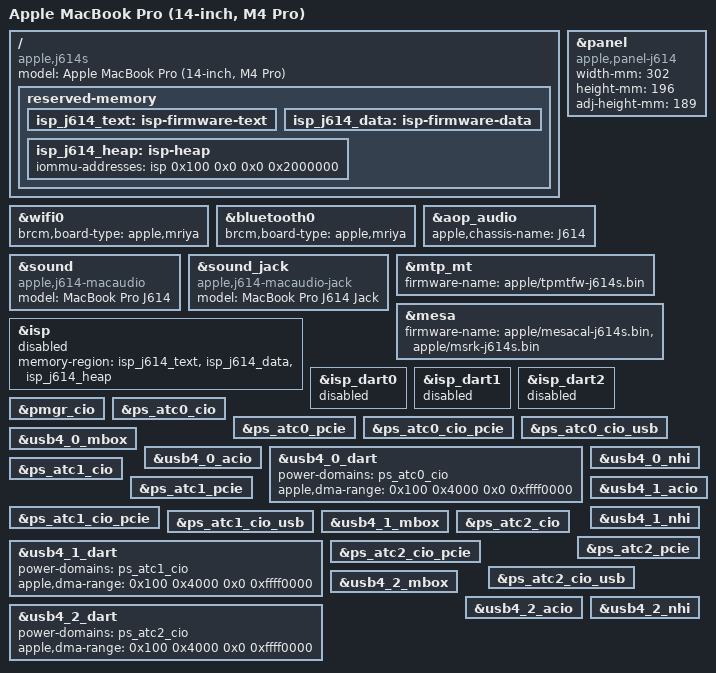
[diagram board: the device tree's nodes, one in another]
// SPDX-License-Identifier: GPL-2.0+ OR MIT
/*
 * MacBook Pro (14-inch, M4 Pro)
 *
 * target-type: J614s
 *
 * Copyright The Asahi Linux Contributors
 */

/dts-v1/;

#include "t6040.dtsi"
#include "t604x-j614-j616.dtsi"

/ {
	compatible = "apple,j614s", "apple,t6040", "apple,arm-platform";
	model = "Apple MacBook Pro (14-inch, M4 Pro)";
};

/* ADT /arm-io/wlan module-instance */
&wifi0 {
	brcm,board-type = "apple,mriya";
};

&bluetooth0 {
	brcm,board-type = "apple,mriya";
};

&panel {
	compatible = "apple,panel-j614", "apple,panel-mini-led", "apple,panel";
	width-mm = <302>;
	height-mm = <196>;
	adj-height-mm = <189>;
};

&aop_audio {
	apple,chassis-name = "J614";
};

/*
 * The speakers, as on the J616s: the same six amps, slots and frame (the
 * boot loader copies each amp's ADT speaker-config row). Playback waits for
 * a protection lease, which speakerguardd v2 takes only after compiling and
 * self-checking this Mac's own tuning; the legacy protection has no J614
 * profile, so without v2 the amps stay at the kernel's floor.
 */
&sound {
	compatible = "apple,j614-macaudio", "apple,macaudio";
	model = "MacBook Pro J614";
};

&sound_jack {
	compatible = "apple,j614-macaudio-jack", "apple,macaudio";
	model = "MacBook Pro J614 Jack";
};

&mtp_mt {
	firmware-name = "apple/tpmtfw-j614s.bin";
};

/*
 * Per-device factory data from this Mac's own iBoot system container: the
 * sealed calibration and the sealed root key.
 */
&mesa {
	firmware-name = "apple/mesacal-j614s.bin", "apple/msrk-j614s.bin";
};

/* The loader reserves this boot's ISP firmware before enabling the camera. */
&isp {
	memory-region = <&isp_j614_text>, <&isp_j614_data>, <&isp_j614_heap>;
	status = "disabled";
};

/delete-node/ &isp_fw_text;
/delete-node/ &isp_fw_data;
/delete-node/ &isp_heap;

/ {
	reserved-memory {
		isp_j614_text: isp-firmware-text { };
		isp_j614_data: isp-firmware-data { };
		isp_j614_heap: isp-heap {
			iommu-addresses = <&isp 0x100 0x0 0x0 0x2000000>;
		};
	};
};

&isp_dart0 {
	status = "disabled";
};

&isp_dart1 {
	status = "disabled";
};

&isp_dart2 {
	status = "disabled";
};

/*
 * USB4/Thunderbolt on all three Type-C ports: typec0 (left back, ACIO0),
 * typec1 (left front, ACIO1) and typec2 (right, ACIO2), as on the J616s: the
 * J614s ADT has the same acio0-2, dart-acio0-2 and acio-cpu0-2. The loader
 * hands each router its router, adapter and NHI tuning and its DROM over. No
 * PCIe tunnels yet: host-to-host (XDomain, thunderbolt-net) and USB4 links
 * only.
 */
&pmgr_cio {
	status = "okay";
};

&ps_atc0_cio {
	status = "okay";
};

&ps_atc0_pcie {
	status = "okay";
};

&ps_atc0_cio_pcie {
	status = "okay";
};

&ps_atc0_cio_usb {
	status = "okay";
};

&usb4_0_mbox {
	status = "okay";
};

&usb4_0_acio {
	/delete-property/ apple,pcie-tunnel;
	status = "okay";
};

&usb4_0_dart {
	power-domains = <&ps_atc0_cio>;
	/* ADT dart-acio0 vm-base: the NHI addresses its rings below 1 TiB + 4 GiB. */
	apple,dma-range = <0x100 0x4000 0x0 0xffff0000>;
	status = "okay";
};

&usb4_0_nhi {
	status = "okay";
};

&ps_atc1_cio {
	status = "okay";
};

&ps_atc1_pcie {
	status = "okay";
};

&ps_atc1_cio_pcie {
	status = "okay";
};

&ps_atc1_cio_usb {
	status = "okay";
};

&usb4_1_mbox {
	status = "okay";
};

&usb4_1_acio {
	/delete-property/ apple,pcie-tunnel;
	status = "okay";
};

&usb4_1_dart {
	power-domains = <&ps_atc1_cio>;
	/* The same DVA window as the ACIO0 router DART. */
	apple,dma-range = <0x100 0x4000 0x0 0xffff0000>;
	status = "okay";
};

&usb4_1_nhi {
	status = "okay";
};

&ps_atc2_cio {
	status = "okay";
};

&ps_atc2_pcie {
	status = "okay";
};

&ps_atc2_cio_pcie {
	status = "okay";
};

&ps_atc2_cio_usb {
	status = "okay";
};

&usb4_2_mbox {
	status = "okay";
};

&usb4_2_acio {
	/delete-property/ apple,pcie-tunnel;
	status = "okay";
};

&usb4_2_dart {
	power-domains = <&ps_atc2_cio>;
	/* The same DVA window as the ACIO0 router DART. */
	apple,dma-range = <0x100 0x4000 0x0 0xffff0000>;
	status = "okay";
};

&usb4_2_nhi {
	status = "okay";
};

#include "t6040-j614s-extdisp-hdmi.dtsi"
